# USCI_A0__SPI_Mode_1 register map
Vendor: Texas Instruments
Peripheral module from a debugger description file (folder msp430).
Registers are 8-bit, access not given, no defined reset value unless marked. A register's access mark holds for its fields unless they carry their own. Offsets are as the file gives them; lines under a group give offsets from that group; [hi:lo] are bit positions; {n}, {i} and the like mark numbered series; 'fields as' and 'values as' point back to an identical list; <NAME> marks a mode.

## USCI_A0_SPI_Mode
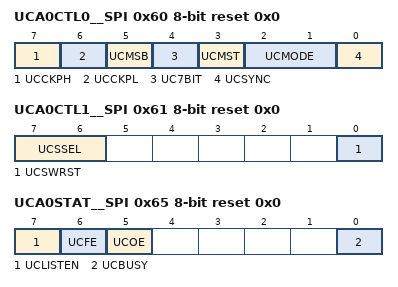
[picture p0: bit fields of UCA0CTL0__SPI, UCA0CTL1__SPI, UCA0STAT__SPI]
0x60 UCA0CTL0__SPI rw reset 0x0 — USCI A0 Control Register 0
  [7] UCCKPH — Sync. Mode: Clock Phase
  [6] UCCKPL — Sync. Mode: Clock Polarity
  [5] UCMSB — Sync. Mode: MSB first 0:LSB / 1:MSB
  [4] UC7BIT — Sync. Mode: Data Bits 0:8-bits / 1:7-bits
  [3] UCMST — Sync. Mode: Master Select
  [2:1] UCMODE — Sync. Mode: USCI Mode 1
    {v}=Sync. Mode: USCI Mode: {v} (v=0..3)
  [0] UCSYNC — Sync-Mode 0:UART-Mode / 1:SPI-Mode
0x61 UCA0CTL1__SPI rw reset 0x0 — USCI A0 Control Register 1
  [7:6] UCSSEL — USCI 1 Clock Source Select 1
    {v}=USCI 0 Clock Source: {v} (v=0..3)
  [0] UCSWRST — USCI Software Reset
0x62 UCA0BR0__SPI — USCI A0 Baud Rate 0
0x63 UCA0BR1__SPI — USCI A0 Baud Rate 1
0x64 UCA0MCTL__SPI — USCI A0 Modulation Control
0x65 UCA0STAT__SPI rw reset 0x0 — USCI A0 Status Register
  [7] UCLISTEN — USCI Listen mode
  [6] UCFE — USCI Frame Error Flag
  [5] UCOE — USCI Overrun Error Flag
  [0] UCBUSY — USCI Busy Flag
0x66 UCA0RXBUF__SPI — USCI A0 Receive Buffer
0x67 UCA0TXBUF__SPI — USCI A0 Transmit Buffer
